# cyt4dn register map
Vendor: Cypress Semiconductor; Series: cyt4dn; File version: 1.0
CPU: CM7 r0p1, little endian, MPU, FPU, VTOR, 3 interrupt priority bits
Registers are 32-bit, read-write, reset 0x0 unless marked. A register's access mark holds for its fields unless they carry their own. Offsets are from the block's base; [hi:lo] are bit positions; lines under a group give offsets from that group; {n}, {i} and the like mark numbered series; 'fields as' and 'values as' point back to an identical list.

## VIDEOSS0 (part 18 of 18) — Video and Graphics Subsystem
Base 0x40A00000
0xE0000 LCDBUSIF group — LCD Bus Interface
  0x00 LOCKUNLOCKLCD reset not defined — Register to change the protection status of this address block.
    [31:0] LOCKUNLOCKLCD — The protection status is changed by writing one of the following key values to this field:
      0x5651F763=LOCK_KEY (Decrements the unlock counter. When the counter value is null, lock protection is active. Reset counter value is 1.); 0x691DB936=UNLOCK_KEY (Increments the unlock counter. Max allowed value is 15.); 0xAEE95CDC=PRIVILEGE_KEY (Enables privilege protection. Disabled after reset.); 0xB5E2466E=UNPRIVILEGE_KEY (Disables privilege protection.); 0xFBE8B1E6=FREEZE_KEY (Freezes current protection status. Writing keys to this register has no more effect until reset.)
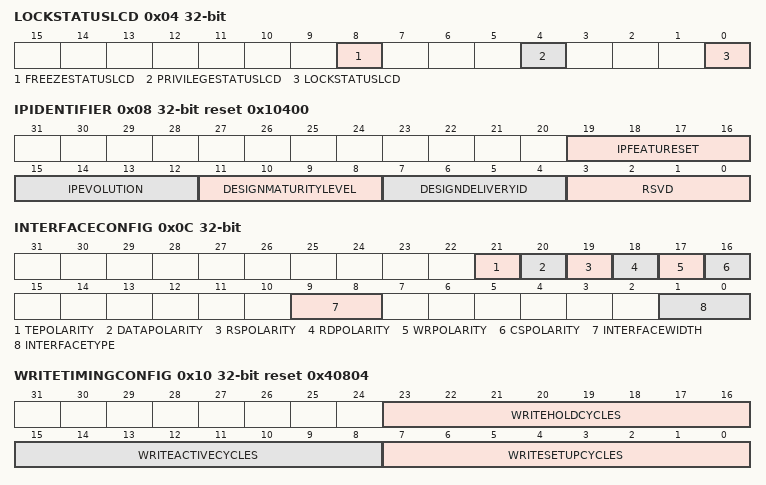
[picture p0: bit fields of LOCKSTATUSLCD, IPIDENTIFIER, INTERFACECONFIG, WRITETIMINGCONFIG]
  0x04 LOCKSTATUSLCD ro — Protection status of this address block.
    [8] FREEZESTATUSLCD — Current freeze status: 0 = protection status can be changed, 1 = cannot be changed.
    [4] PRIVILEGESTATUSLCD — Current status of privilege protection: 0 = inactive , 1 = active.
    [0] LOCKSTATUSLCD — Current status of lock protection: 0 = inactive (unlock counter > 0), 1 = active (unlock counter == 0).
  0x08 IPIDENTIFIER reset 0x10400 — IP Identifier for this LCDBusIF derivate, needs to be unlocked.
    [19:16] IPFEATURESET — IP feature set (complexity of implemented features, e.g. availability of re-sampling filter etc)
      0=LIGHT (LCDBusIF without data master functionality.); 1=STANDARD (LCDBusIF with data master functionality.)
    [15:12] IPEVOLUTION — IP evolution (increased for functional spec changes only when feature set keeps the same)
    [11:8] DESIGNMATURITYLEVEL — Design maturity level (corresponds to status at time of IP delivery, Fujitsu internal development stages)
      1=PREFS (Pre feasibility study); 2=FS (Feasibility study); 3=R0 (Functionality complete); 4=R1 (Verification complete)
    [7:4] DESIGNDELIVERYID — Design delivery ID (increased with each official delivery when maturity keeps the same)
    [3:0] RSVD
  0x0C INTERFACECONFIG — LCDBus interface configuration register.
    [21] TEPOLARITY — Polarity for tearing effect input.
      0=ACTIVE_HIGH (TE is a high active signal.); 1=ACTIVE_LOW (TE is a low active signal.)
    [20] DATAPOLARITY — Inversion for data signals upon write.
      0=DEFAULT (Data bus is used as is.); 1=INVERTED (Data bus is inverted.)
    [19] RSPOLARITY — Polarity of register select output.
      0=COMMAND_LOW (RS is command with low signal level.); 1=COMMAND_HIGH (RS is command with high signal level.)
    [18] RDPOLARITY — Polarity for RD# (8080) or E (6800) output.
      0=DEFAULT (RD# (E) has default protocol polarity.); 1=INVERTED (RD# (E) has inverted protocol polarity.)
    [17] WRPOLARITY — Polarity for WR# (8080) or R/W# (6800) otuput.
      0=DEFAULT (WR# (R/W#) has default protocol polarity.); 1=INVERTED (WR# (R/W#) has inverted protocol polarity.)
    [16] CSPOLARITY — Polarity for chip select output.
      0=ACTIVE_LOW (CS is a low active signal.); 1=ACTIVE_HIGH (CS is a high active signal.)
    [9:8] INTERFACEWIDTH — Describes the data width of the external interface.
      0=LCD8 (8-bit LCDBus); 1=LCD9 (9-bit LCDBus); 2=LCD16 (16-bit LCDBus); 3=LCD18 (18-bit LCDBus)
    [1:0] INTERFACETYPE — Describes the type of the external interface.
      0=INTEL80_TYPE1 (Intel 8080 compatible interface (strobe with RD#/WR#).); 1=INTEL80_TYPE2 (Intel 8080 compatible interface (strobe with CS#).); 2=MOTOROLA68_TYPE1 (Motorola 6800 compatible interface (strobe with E).); 3=MOTOROLA68_TYPE2 (Motorola 6800 compatible interface (strobe with CS#).)
  0x10 WRITETIMINGCONFIG reset 0x40804 — Write timing configuration register. Sum of all fields is write cycle time in module clock cycles.
    [23:16] WRITEHOLDCYCLES — Number of module clock cycles minus one to wait after wr#/cs#/en terminal became inactive before address can change (tAH).
    [15:8] WRITEACTIVECYCLES — Number of module clock cycles minus one wr#/cs#/en terminal should remain active (tCCLW).
    [7:0] WRITESETUPCYCLES — Number of module clock cycles minus one to wait before wr#/cs#/en terminal can become active after address set (tAW).
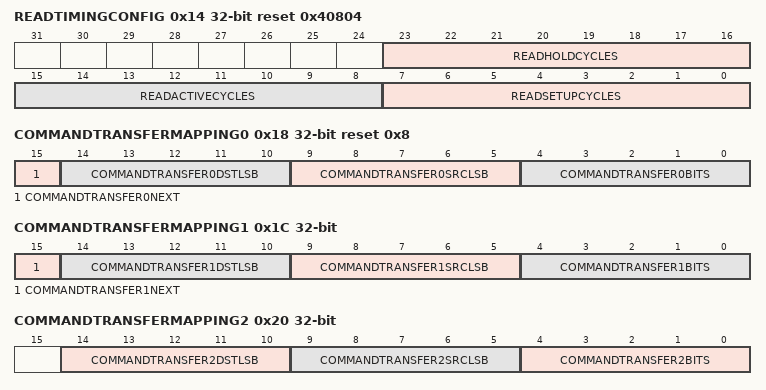
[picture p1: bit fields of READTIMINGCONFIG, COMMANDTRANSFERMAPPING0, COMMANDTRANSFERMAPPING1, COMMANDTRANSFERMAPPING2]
  0x14 READTIMINGCONFIG reset 0x40804 — Read timing configuration register. Sum of all fields is read cycle time in module clock cycles.
    [23:16] READHOLDCYCLES — Number of module clock cycles minus one to wait after rd#/cs#/en terminal became inactive before address can change (tAH).
    [15:8] READACTIVECYCLES — Number of module clock cycles minus one rd#/cs#/en terminal should remain active (tCCLR).
    [7:0] READSETUPCYCLES — Number of module clock cycles minus one to wait before rd#/cs#/en terminal can become active after address set (tAW).
  0x18 COMMANDTRANSFERMAPPING0 reset 0x8 — Transfer mapping for command data on LCDBus.
    [15] COMMANDTRANSFER0NEXT — If set, a second transfer will be required to transmit the command data, see CommandTransferMapping1.
    [14:10] COMMANDTRANSFER0DSTLSB — Least significant bit in destination word (Wr=Interface data, Rd=RxFifo) to insert vector into (first transfer).
    [9:5] COMMANDTRANSFER0SRCLSB — Least significant bit of vector to extract from source (Wr=InstructionFifo, Rd=Interface data) (first transfer).
    [4:0] COMMANDTRANSFER0BITS — Number of bits from InstructionFifo to be transfered with first transfer. Must be greater than 0.
  0x1C COMMANDTRANSFERMAPPING1 — Transfer mapping for command data on LCDBus.
    [15] COMMANDTRANSFER1NEXT — If set, a third transfer will be required to transmit the command data, see CommandTransferMapping2.
    [14:10] COMMANDTRANSFER1DSTLSB — Least significant bit in destination word (Wr=Interface data, Rd=RxFifo) to insert vector into (second transfer).
    [9:5] COMMANDTRANSFER1SRCLSB — Least significant bit of vector to extract from source (Wr=InstructionFifo, Rd=Interface data) (second transfer).
    [4:0] COMMANDTRANSFER1BITS — Number of bits from InstructionFifo to be transfered with second transfer. Must be greater than 0 if CommandTransfer0Next is set.
  0x20 COMMANDTRANSFERMAPPING2 — Transfer mapping for command data on LCDBus.
    [14:10] COMMANDTRANSFER2DSTLSB — Least significant bit in destination word (Wr=Interface data, Rd=RxFifo) to insert vector into (third transfer).
    [9:5] COMMANDTRANSFER2SRCLSB — Least significant bit of vector to extract from source (Wr=InstructionFifo, Rd=Interface data) (third transfer).
    [4:0] COMMANDTRANSFER2BITS — Number of bits from InstructionFifo to be transfered with third transfer.
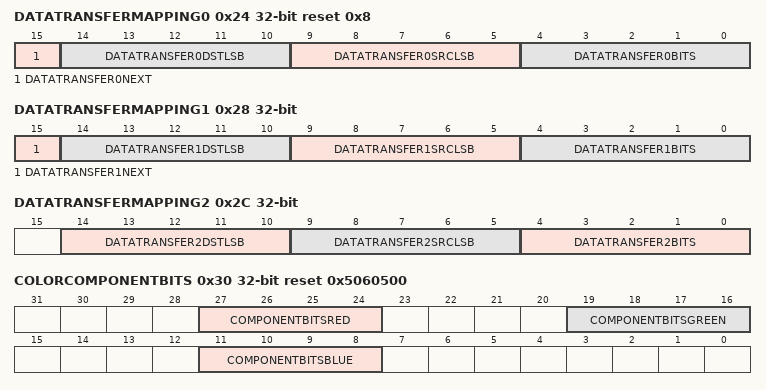
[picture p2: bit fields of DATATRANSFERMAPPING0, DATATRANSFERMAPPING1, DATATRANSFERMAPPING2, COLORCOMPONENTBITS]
  0x24 DATATRANSFERMAPPING0 reset 0x8 — Transfer mapping for data/parameter data on LCDBus.
    [15] DATATRANSFER0NEXT — If set, second transfer will be required to transmit a data word.
    [14:10] DATATRANSFER0DSTLSB — Least significant bit in destination word (Wr=Interface data, Rd=RxFifo) to insert vector into (first transfer).
    [9:5] DATATRANSFER0SRCLSB — Least significant bit of vector to extract from source (Wr=InstructionFifo, Rd=Interface data) (first transfer).
    [4:0] DATATRANSFER0BITS — Number of bits from DataFifo to be transfered with first transfer.
  0x28 DATATRANSFERMAPPING1 — Transfer mapping for data/parameter data on LCDBus.
    [15] DATATRANSFER1NEXT — If set, third transfer will be required to transmit a data word.
    [14:10] DATATRANSFER1DSTLSB — Least significant bit in destination word (Wr=Interface data, Rd=RxFifo) to insert vector into (second transfer).
    [9:5] DATATRANSFER1SRCLSB — Least significant bit of vector to extract from source (Wr=InstructionFifo, Rd=Interface data) (second transfer).
    [4:0] DATATRANSFER1BITS — Number of bits from DataFifo to be transfered with second transfer.
  0x2C DATATRANSFERMAPPING2 — Transfer mapping for data/parameter data on LCDBus.
    [14:10] DATATRANSFER2DSTLSB — Least significant bit in destination word (Wr=Interface data, Rd=RxFifo) to insert vector into (third transfer).
    [9:5] DATATRANSFER2SRCLSB — Least significant bit of vector to extract from source (Wr=InstructionFifo, Rd=Interface data) (third transfer).
    [4:0] DATATRANSFER2BITS — Number of bits from DataFifo to be transfered with third transfer.
  0x30 COLORCOMPONENTBITS reset 0x5060500 — Color component size for color format of LCD controller.
    [27:24] COMPONENTBITSRED — Red component bits.
    [19:16] COMPONENTBITSGREEN — Green component bits.
    [11:8] COMPONENTBITSBLUE — Blue component bits.
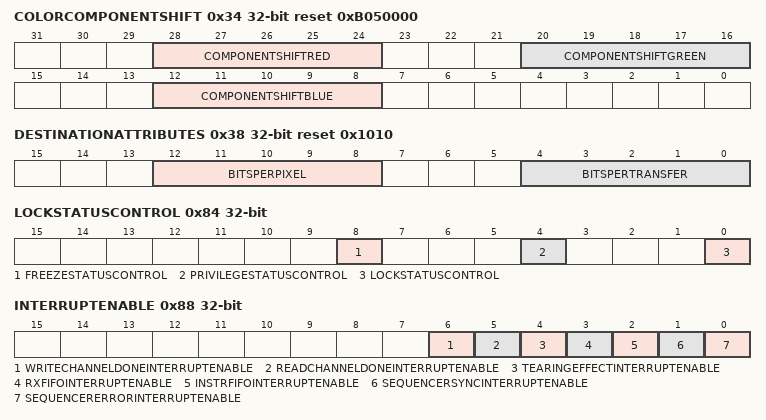
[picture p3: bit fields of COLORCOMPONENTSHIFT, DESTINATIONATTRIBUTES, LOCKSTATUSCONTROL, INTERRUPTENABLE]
  0x34 COLORCOMPONENTSHIFT reset 0xB050000 — Color component offset for color format of LCD controller.
    [28:24] COMPONENTSHIFTRED — Red component shift.
    [20:16] COMPONENTSHIFTGREEN — Green component shift.
    [12:8] COMPONENTSHIFTBLUE — Blue component shift.
  0x38 DESTINATIONATTRIBUTES reset 0x1010 — Configuration for packing unit.
    [12:8] BITSPERPIXEL — How many bits are required for one pixel.
    [4:0] BITSPERTRANSFER — How many bits can be packed into one transfer (allows packing multiple bits into one LCDBus transfer).
  0x80 LOCKUNLOCKCONTROL reset not defined — Register to change the protection status of this address block.
    [31:0] LOCKUNLOCKCONTROL — The protection status is changed by writing one of the following key values to this field:
      values as LCDBUSIF.LOCKUNLOCKLCD.LOCKUNLOCKLCD
  0x84 LOCKSTATUSCONTROL ro — Protection status of this address block.
    [8] FREEZESTATUSCONTROL — Current freeze status: 0 = protection status can be changed, 1 = cannot be changed.
    [4] PRIVILEGESTATUSCONTROL — Current status of privilege protection: 0 = inactive , 1 = active.
    [0] LOCKSTATUSCONTROL — Current status of lock protection: 0 = inactive (unlock counter > 0), 1 = active (unlock counter == 0).
  0x88 INTERRUPTENABLE — LCD Bus Interface interrupt enable register
    [6] WRITECHANNELDONEINTERRUPTENABLE — If set to '1' the WriteChannelDone interupt is enabled, if set to '0' the interrupt is disabled and only the InterruptStatus register can be used to see the status.
    [5] READCHANNELDONEINTERRUPTENABLE — If set to '1' the ReadChannelDone interupt is enabled, if set to '0' the interrupt is disabled and only the InterruptStatus register can be used to see the status.
    [4] TEARINGEFFECTINTERRUPTENABLE — If set to '1' the TearingEffect interupt is enabled, if set to '0' the interrupt is disabled and only the InterruptStatus register can be used to see the status.
    [3] RXFIFOINTERRUPTENABLE — If set to '1' the RxFifo interupt is enabled, if set to '0' the interrupt is disabled and only the InterruptStatus register can be used to see the status.
    [2] INSTRFIFOINTERRUPTENABLE — If set to '1' the TxFifo interupt is enabled, if set to '0' the interrupt is disabled and only the InterruptStatus register can be used to see the status.
    [1] SEQUENCERSYNCINTERRUPTENABLE — If set to '1' the SequencerSync interupt is enabled, if set to '0' the interrupt is disabled and only the InterruptStatus register can be used to see the status.
    [0] SEQUENCERERRORINTERRUPTENABLE — If set to '1' the SequencerError interupt is enabled, if set to '0' the interrupt is disabled and only the InterruptStatus register can be used to see the status.
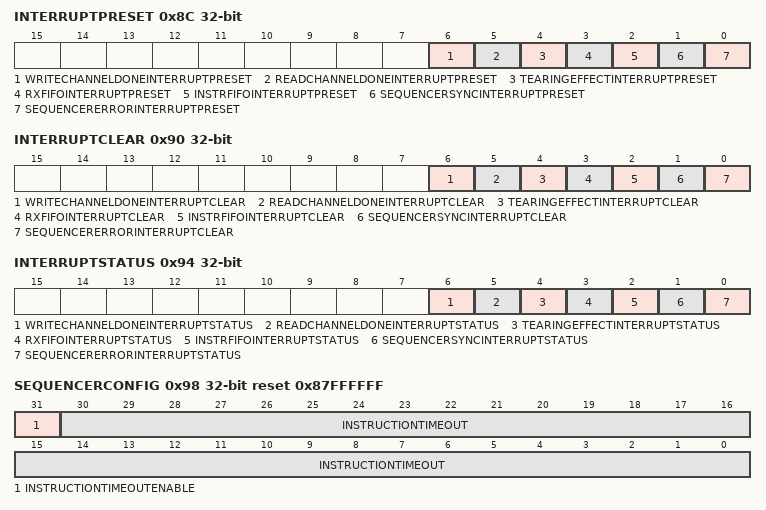
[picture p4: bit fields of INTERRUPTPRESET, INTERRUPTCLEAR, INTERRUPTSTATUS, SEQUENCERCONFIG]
  0x8C INTERRUPTPRESET wo reset not defined — LCD Bus Interface interrupt preset register
    [6] WRITECHANNELDONEINTERRUPTPRESET — Write '1' to this field to set the WriteChannelDone interrupt.
    [5] READCHANNELDONEINTERRUPTPRESET — Write '1' to this field to set the ReadChannelDone interrupt.
    [4] TEARINGEFFECTINTERRUPTPRESET — Write '1' to this field to set the TearingEffect interrupt.
    [3] RXFIFOINTERRUPTPRESET — Write '1' to this field to set the RxFifo interrupt.
    [2] INSTRFIFOINTERRUPTPRESET — Write '1' to this field to set the TxFifo interrupt.
    [1] SEQUENCERSYNCINTERRUPTPRESET — Write '1' to this field to set the SequencerSync interrupt.
    [0] SEQUENCERERRORINTERRUPTPRESET — Write '1' to this field to set the SequencerError interrupt.
  0x90 INTERRUPTCLEAR wo reset not defined — LCD Bus Interface interrupt clear register
    [6] WRITECHANNELDONEINTERRUPTCLEAR — Write '1' to this field to clear the WriteChannelDone interrupt.
    [5] READCHANNELDONEINTERRUPTCLEAR — Write '1' to this field to clear the ReadChannelDone interrupt.
    [4] TEARINGEFFECTINTERRUPTCLEAR — Write '1' to this field to clear the TearingEffect interrupt.
    [3] RXFIFOINTERRUPTCLEAR — Write '1' to this field to clear the RxFifo interrupt.
    [2] INSTRFIFOINTERRUPTCLEAR — Write '1' to this field to clear the TxFifo interrupt.
    [1] SEQUENCERSYNCINTERRUPTCLEAR — Write '1' to this field to clear the SequencerSync interrupt.
    [0] SEQUENCERERRORINTERRUPTCLEAR — Write '1' to this field to clear the SequencerError interrupt.
  0x94 INTERRUPTSTATUS ro — LCD Bus Interface interrupt status register
    [6] WRITECHANNELDONEINTERRUPTSTATUS — Status of the WriteChannelDone interrupt.
    [5] READCHANNELDONEINTERRUPTSTATUS — Status of the ReadChannelDone interrupt.
    [4] TEARINGEFFECTINTERRUPTSTATUS — Status of the TearingEffect interrupt.
    [3] RXFIFOINTERRUPTSTATUS — Status of the RxFifo interrupt.
    [2] INSTRFIFOINTERRUPTSTATUS — Status of the TxFifo interrupt.
    [1] SEQUENCERSYNCINTERRUPTSTATUS — Status of the SequencerSync interrupt.
    [0] SEQUENCERERRORINTERRUPTSTATUS — Status of the SequencerError interrupt.
  0x98 SEQUENCERCONFIG reset 0x87FFFFFF — Sequencer configuration register.
    [31] INSTRUCTIONTIMEOUTENABLE — Enable or disable instruction timeout counter.
    [30:0] INSTRUCTIONTIMEOUT — Value to preload the timeout counter with each instruction read.
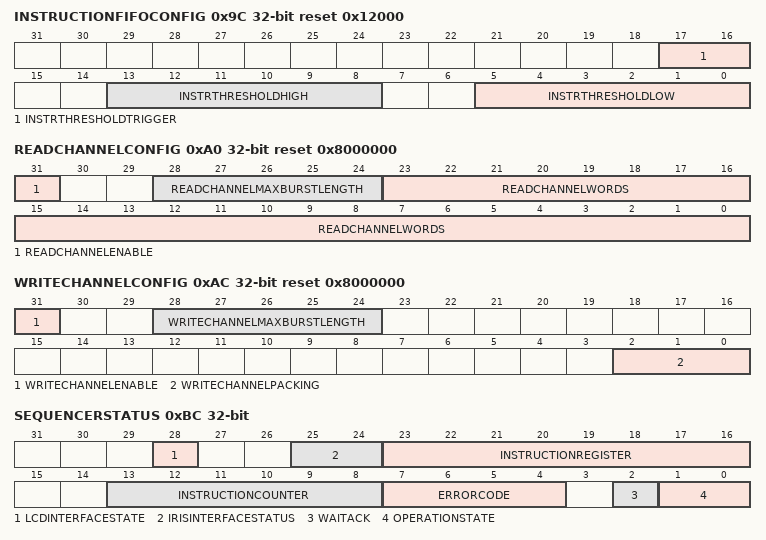
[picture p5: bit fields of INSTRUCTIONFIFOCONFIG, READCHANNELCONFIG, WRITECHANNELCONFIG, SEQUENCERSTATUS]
  0x9C INSTRUCTIONFIFOCONFIG reset 0x12000 — Instruction fifo configuration register.
    [17:16] INSTRTHRESHOLDTRIGGER — Select trigger condition for InstrFifoInterrupt.
      0=LOW (InstrFifoInterrupt triggers if level falls below low threshold after being above high level.); 1=HIGH (InstrFifoInterrupt triggers if level raises above high threshold after being below low level.); 2=BOTH (InstrFifoInterrupt triggers for both low and high threshold conditions.)
    [13:8] INSTRTHRESHOLDHIGH — The threshold above which the instruction fifo should generate a high interrupt.
    [5:0] INSTRTHRESHOLDLOW — The threshold below which the instruction fifo should generate a low interrupt.
  0xA0 READCHANNELCONFIG reset 0x8000000 — Read Channel Configuration Register.
    [31] READCHANNELENABLE — Enable read channel interface. Locks the InstructionFifo from configuration interface.
    [28:24] READCHANNELMAXBURSTLENGTH — Default burstlength for read channel requests. Will always be used except for the last access if remaining words is less than ReadChannelMaxBurstLength.
    [23:0] READCHANNELWORDS — Set to number of 32-bit words to read minus 1.
  0xA4 READCHANNELBUFFER — Read Channel Buffer Configuration Register.
    [31:0] READCHANNELBASEADDRESS — Base address of read buffer. Must be 32-bit aligned.
  0xA8 READCHANNELCONTROL wo
    [0] READCHANNELTRIGGER — Initiate read of data via read channel interface.
  0xAC WRITECHANNELCONFIG reset 0x8000000 — Write Channel Configuration Register.
    [31] WRITECHANNELENABLE — Enable write channel interface. Locks the RxFifo from configuration interface.
    [28:24] WRITECHANNELMAXBURSTLENGTH — Default burstlength for write channel requests. Will always be used except for the last access if remaining words is less than WriteChannelMaxBurstLength.
    [2:0] WRITECHANNELPACKING — Set write channel packing configuration.
      0=DISABLED (Write LCDBus read data as mapped into reception fifo.); 1=BPP16 (Pack 16-bit pixel data into 32-bit memory transfers.); 2=BPP8 (Pack 8-bit pixel data into 32-bit memory transfers.); 3=RSVD (N/A); 4=BPP18TIGHT (Pack 18-bit pixel data into 32-bit memory transfers.)
  0xB0 WRITECHANNELBUFFER — Write Channel Buffer Configuration Register.
    [31:0] WRITECHANNELBASEADDRESS — Base address of write buffer. Must be 32-bit aligned.
  0xB4 SOFTWARERESET wo reset not defined
    [0] SOFTWARERESET — Writting a 1 to this field will reset all fifos and control logic of LCDBusIF.
  0xB8 SEQUENCERSYNC wo reset not defined — Sequencer synchronization register.
    [0] SEQUENCERACK — A write to this bit will allow the sequencer to continue from the WAIT_ACK instruction.
  0xBC SEQUENCERSTATUS ro (reset mask 0x13FF00F7) — Status of the internal sequencer.
    [28] LCDINTERFACESTATE — Indicate LCDBus status.
      0=IDLE (No transactions pending.); 1=BUSY (Currently sending transactions.)
    [25:24] IRISINTERFACESTATUS — Status of Iris interface.
      0=IDLE (Nothing pending.); 1=KICK (Kick sent, frame pending.); 2=CMD (Command received, pixel transmission pending.); 3=FRAME (Frame transmission ongoing.)
    [23:16] INSTRUCTIONREGISTER — Current instruction executed by sequencer.
      0=NOP (Currently executing NOP instruction.); 16=IR_SET (Currently executing IR_SET instruction.); 17=IR_GET (Currently executing IR_GET instruction.); 18=DR_SET (Currently executing DR_SET instruction.); 19=DR_GET (Currently executing DR_GET instruction.); 20=DUMMY_GET (Currently executing DUMMY_GET instruction.); 21=WAIT_TE (Currently executing WAIT_TE instruction.); 22=WAIT_IF (Currently executing WAIT_IF instruction.); 31=SET_RESET (Currently executing SET_RESET instruction.); 32=SEND_IRQ (Currently executing SEND_IRQ instruction.); 33=WAIT_ACK (Currently executing WAIT_ACK instruction.); 64=IRIS_KICK (Currently executing IRIS_KICK instruction.); 65=WAIT_CMD (Currently executing WAIT_CMD instruction.); 66=IRIS_FRAME (Currently executing IRIS_FRAME instruction.); 128=WR_PIXEL (Currently executing WR_PIXEL instruction.); 192=CLUT_CFG (Currently executing CLUT_CFG instruction.); 255=END (Currently executing END instruction.)
    [13:8] INSTRUCTIONCOUNTER — Number of instructions processed in current command list.
    [7:4] ERRORCODE — Type of error that has occured
      0=NONE (No error.); 1=OPCODE (Illegal opcode error.); 2=KICK (Too many outstanding kicks error.); 3=TIMEOUT (Sequencer timout reached.)
    [2] WAITACK — Indicate if a WAIT_ACK instruction is currently pending.
      0=DONE (No waiting for acknowledge.); 1=PENDING (Acknowledge from CPU is pending.)
    [1:0] OPERATIONSTATE — Indicate operation status.
      0=IDLE (Processing finished, nothing to do.); 1=BUSY (Currently processing instruction list.); 2=WAIT (Waiting for next instruction or data.); 3=ERROR (An error has occured)
  0xC0 SEQUENCERTRANSFERSTATUS ro — Transfer remaining of current executed command.
    [27:0] TRANSFERREMAINING — Internal counter of the sequencer for current executed instruction NOP, IR_GET, DR_GET, WR_PIXEL or IRIS_FRAME.
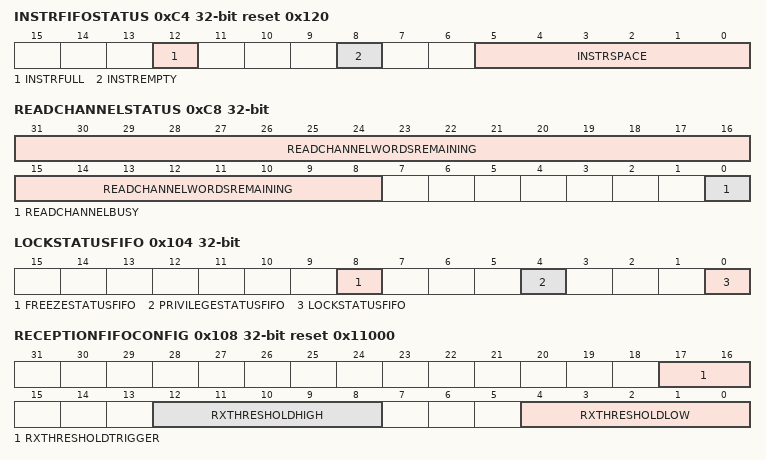
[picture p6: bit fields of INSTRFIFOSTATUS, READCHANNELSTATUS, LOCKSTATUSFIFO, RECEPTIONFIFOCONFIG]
  0xC4 INSTRFIFOSTATUS ro reset 0x120 — Instruction fifo status register.
    [12] INSTRFULL — Indicates if InstructionFifo is full.
    [8] INSTREMPTY — Indicates if InstructionFifo is empty.
    [5:0] INSTRSPACE — Available space in InstructionregistFifo in number of entries.
  0xC8 READCHANNELSTATUS ro
    [31:8] READCHANNELWORDSREMAINING — Number of 32-bit words still to be read.
    [0] READCHANNELBUSY — Status indication for read channel interface.
      0=IDLE (No operation.); 1=BUSY (Reading data.)
  0xCC WRITECHANNELSTATUS ro
    [0] WRITECHANNELBUSY — Status indication for write channel interface.
      0=IDLE (No operation.); 1=BUSY (Writeing data.)
  0x100 LOCKUNLOCKFIFO reset not defined — Register to change the protection status of the fifo address blocks.
    [31:0] LOCKUNLOCKFIFO — The protection status is changed by writing one of the following key values to this field:
      values as LCDBUSIF.LOCKUNLOCKLCD.LOCKUNLOCKLCD
  0x104 LOCKSTATUSFIFO ro — Protection status of this address block.
    [8] FREEZESTATUSFIFO — Current freeze status: 0 = protection status can be changed, 1 = cannot be changed.
    [4] PRIVILEGESTATUSFIFO — Current status of privilege protection: 0 = inactive , 1 = active.
    [0] LOCKSTATUSFIFO — Current status of lock protection: 0 = inactive (unlock counter > 0), 1 = active (unlock counter == 0).
  0x108 RECEPTIONFIFOCONFIG reset 0x11000 — Reception fifo configuration register.
    [17:16] RXTHRESHOLDTRIGGER — Select trigger condition for RxFifoInterrupt.
      0=LOW (RxFifoInterrupt triggers if level falls below low threshold after being above high level.); 1=HIGH (RxFifoInterrupt triggers if level raises above high threshold after being below low level.); 2=BOTH (RxFifoInterrupt triggers for both low and high threshold conditions.)
    [12:8] RXTHRESHOLDHIGH — The threshold above which the reception fifo should generate a high interrupt.
    [4:0] RXTHRESHOLDLOW — The threshold below which the reception fifo should generate a low interrupt.
  0x10C RXFIFOCONTROL wo reset not defined — Reception fifo control register.
    [0] RXCLEAR — Writting a 1 to this field will clear the contents of the RxFifo only.
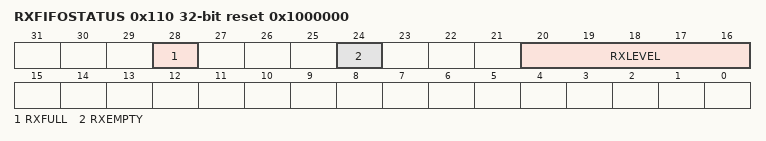
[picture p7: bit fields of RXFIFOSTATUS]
  0x110 RXFIFOSTATUS ro reset 0x1000000 — Reception fifo status register.
    [28] RXFULL — Indicates if RxFifo is full.
    [24] RXEMPTY — Indicates if RxFifo is empty.
    [20:16] RXLEVEL — Number of entries in RxFifo.
  {0x200+4j} INSTRUCTIONFIFO[{j}] (j=0..31) reset not defined
    [31:0] INSTRUCTION — Command instructions to be executed by the sequencer.
  {0x300+4j} RXFIFO[{j}] (j=0..15) reset not defined — Reception Fifo.
    [17:0] RXENTRY — Data received from the LCDBus.
  {0x400+4j} COLORLOOKUPTABLE[{j}] (j=0..255) reset not defined — Color lookup table memory.
    [17:0] CLUTENTRY — ClutEntry in LCD controller target color format (up to 18-bit).
